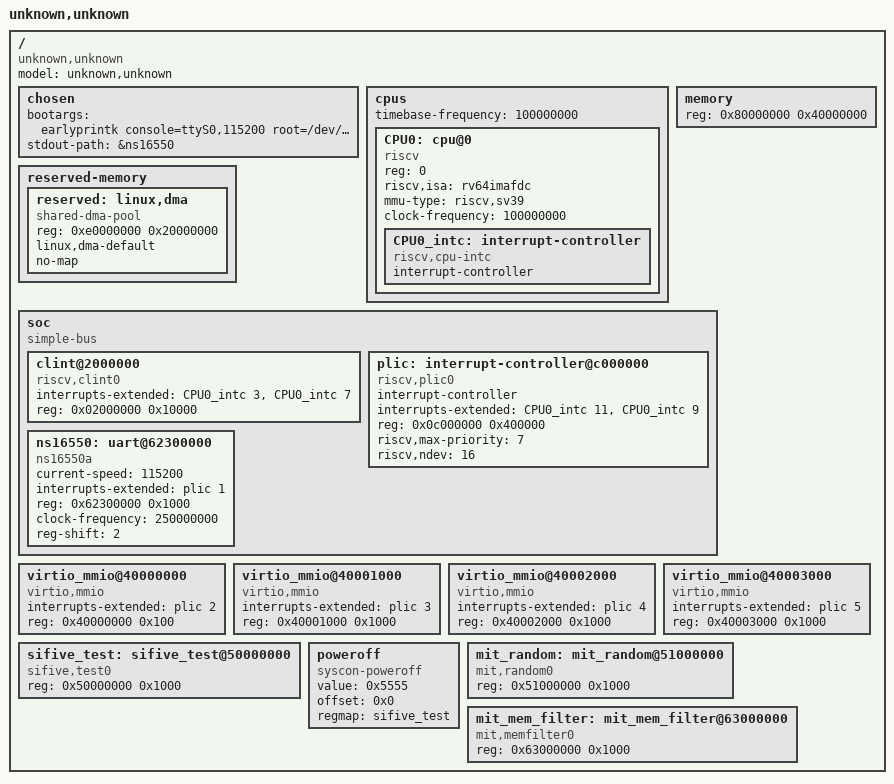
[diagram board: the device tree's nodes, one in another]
/dts-v1/;

/ {
	#address-cells = <1>;
	#size-cells = <1>;
	compatible = "unknown,unknown";
	model = "unknown,unknown";
	chosen {
		bootargs = "earlyprintk console=ttyS0,115200 root=/dev/vda loglevel=15";
		stdout-path = &ns16550;
	};
	cpus {
		#address-cells = <1>;
		#size-cells = <0>;
		timebase-frequency = <100000000>;
		CPU0: cpu@0 {
			device_type = "cpu";
			reg = <0>;
			status = "okay";
			compatible = "riscv";
			riscv,isa = "rv64imafdc";
			mmu-type = "riscv,sv39";
			clock-frequency = <100000000>;
			CPU0_intc: interrupt-controller {
				#interrupt-cells = <1>;
				interrupt-controller;
				compatible = "riscv,cpu-intc";
			};
		};
	};
	memory {
		device_type = "memory";
		reg = <0x80000000 0x40000000>;
	};
	reserved-memory {
		#address-cells = <1>;
		#size-cells = <1>;
		ranges;

		reserved: linux,dma {
			compatible = "shared-dma-pool";
			reg = <0xe0000000 0x20000000>;
			linux,dma-default;
			no-map;
		};
	};
	soc {
		#address-cells = <1>;
		#size-cells = <1>;
		compatible = "simple-bus";
		ranges;
		clint@2000000 {
			compatible = "riscv,clint0";
			interrupts-extended = <&CPU0_intc 3 &CPU0_intc 7>;
			reg = <0x02000000 0x10000>;
		};
		plic: interrupt-controller@c000000 {
			#interrupt-cells = <1>;
			compatible = "riscv,plic0";
			interrupt-controller;
			interrupts-extended = <&CPU0_intc 11 &CPU0_intc 9>;
			reg = <0x0c000000 0x400000>;
			reg-names = "control";
			riscv,max-priority = <7>;
			riscv,ndev = <16>;
		};
		ns16550: uart@62300000 {
			current-speed = <115200>;
			compatible = "ns16550a";
			interrupts-extended = <&plic 1>;
			reg = <0x62300000 0x1000>;
			clock-frequency = <250000000>;
			reg-shift = <2>;
		};
	};

	virtio_mmio@40000000 {
		compatible = "virtio,mmio";
		interrupts-extended = <&plic 2>;
		reg = <0x40000000 0x100>;
	};
	virtio_mmio@40001000 {
		compatible = "virtio,mmio";
		interrupts-extended = <&plic 3>;
		reg = <0x40001000 0x1000>;
	};
	virtio_mmio@40002000 {
		compatible = "virtio,mmio";
		interrupts-extended = <&plic 4>;
		reg = <0x40002000 0x1000>;
	};
	virtio_mmio@40003000 {
		compatible = "virtio,mmio";
		interrupts-extended = <&plic 5>;
		reg = <0x40003000 0x1000>;
	};

	sifive_test: sifive_test@50000000 {
		reg = <0x50000000 0x1000>;
		compatible = "sifive,test0", "syscon";
	};

	poweroff {
		value = <0x5555>;
		offset = <0x0>;
		regmap = <&sifive_test>;
		compatible = "syscon-poweroff";
	};

	mit_random: mit_random@51000000 {
		reg = <0x51000000 0x1000>;
		compatible = "mit,random0";
	};

	mit_mem_filter: mit_mem_filter@63000000 {
		reg = <0x63000000 0x1000>;
		compatible = "mit,memfilter0";
	};

};
